# headsail register map
Vendor: tuni.fi; File version: 1.0
CPU: other r1p0, little endian, no MPU, no FPU, vendor SysTick, 2 interrupt priority bits
Registers are 32-bit, read-write, no defined reset value unless marked. A register's access mark holds for its fields unless they carry their own. Offsets are from the block's base; [hi:lo] are bit positions; lines under a group give offsets from that group; {n}, {i} and the like mark numbered series; <NAME> marks a mode.

## DMA0 — The Excel of Register Map can be found here. <https://tuni.sharepoint.com/:x:/r/sites/TG-SoC-Hub/_layouts/15/Doc.aspx?sourcedoc=%7B971A5DEF-758E-4A18-8EA3-0F3F2D60F0BB%7D&file=DMA_register_map.xlsx&action=default&mobileredirect=true&cid=419a13fc-9dbd-45b9-8f31-77899c555ace> DMA Sub System Document available in below link: <https://tuni.sharepoint.com/:w:/r/sites/TG-SoC-Hub/_layouts/15/Doc.aspx?sourcedoc=%7B9E9DFD0D-B0CA-436B-ABA0-57DB3B73560E%7D&file=DMA_Sub_System_Document.....docx&action=default&mobileredirect=true>
Base 0x1FFA00000
Same registers: DMA1 0x1FFA08000
0x00 status group
  0x00 IP_ID ro — Constant 32'h70646d61 default value ; "pdma" in ascii
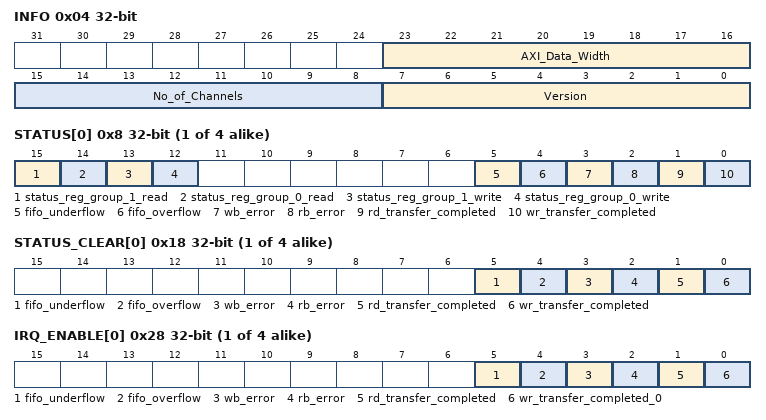
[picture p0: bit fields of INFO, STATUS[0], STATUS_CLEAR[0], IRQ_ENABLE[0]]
  0x04 INFO ro — 32'h00200401 default value Version number Number of available channels AXI data width
    [23:16] AXI_Data_Width, [15:8] No_of_Channels, [7:0] Version
  {0x8+4j} STATUS[{j}] (j=0..3) ro — Holds status flags for Channel(0-3). Each Status Flag can either be cleared by writing to the STATUS_CLEAR register or when the STATUS register is read (must be configured) Status bits of Reg Groups should be read by CPU '0' = Reg Group is Idle '1' = Hardware is using specific reg group
    [15] status_reg_group_1_read, [14] status_reg_group_0_read, [13] status_reg_group_1_write, [12] status_reg_group_0_write, [5] fifo_underflow, [4] fifo_overflow, [3] wb_error, [2] rb_error, [1] rd_transfer_completed, [0] wr_transfer_completed
  {0x18+4j} STATUS_CLEAR[{j}] (j=0..3) — Acknowledging status register for Channels(0-3). Clearing each one by setting corresponding bit
    [5] fifo_underflow, [4] fifo_overflow, [3] wb_error, [2] rb_error, [1] rd_transfer_completed, [0] wr_transfer_completed
  {0x28+4j} IRQ_ENABLE[{j}] (j=0..3) — Configuring which of the interrupts are routed to the IRQ pin for Channels(0-3). Enabling each intterupt signal by setting corresponding bit. All of the interrupts can be enabled and disabled independent from each other.
    [5] fifo_underflow, [4] fifo_overflow, [3] wb_error, [2] rb_error, [1] rd_transfer_completed, [0] wr_transfer_completed_0
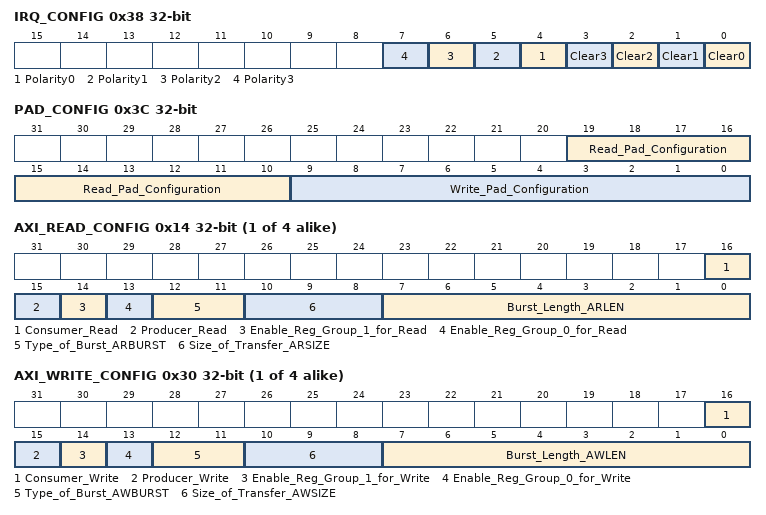
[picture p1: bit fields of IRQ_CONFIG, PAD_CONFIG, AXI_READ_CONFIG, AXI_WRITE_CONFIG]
  0x38 IRQ_CONFIG — Configures the state (active high/low) and clearing conditions for the IRQ pin. Cleared: '0' = Use STATUS_CLEAR to clear '1' = Auto Clear on Read of STATUS register Polarity: '0' = IRQ active low '1' = IRQ active high Set all bits IRQ_CONFIG(7 downto 4) of polarity to "1111" for IRQ active high or "0000" for IRQ active low.
    [n+4] Polarity{n} (n=0..3), [n] Clear{n} (n=0..3)
  0x3C PAD_CONFIG — Configures Pad, 10 Bits for read pad configuration 10 bits for write pad configuration.
    [19:10] Read_Pad_Configuration, [9:0] Write_Pad_Configuration
{0x40+0x80*i} channel{i} group (i=0..3)
  0x00 SOURCE_ADDR — Start address for read
    [31:0] Source_Address
  0x04 SOURCE_LENGTH — Length of read transfer in bytes
  0x08 SOURCE_MODE — ATM only used for initiating a transfer with write to least significant bit. LSB is unset once transfer is started, until then the address and length registers must not be modified.
  0x0C SOURCE_MODE_SET wo — Write to set source mode register
  0x10 SOURCE_MODE_UNSET wo — Write to unset source mode register
  0x14 AXI_READ_CONFIG — AXI configuration signals for read Enable should be done by CPU '0' = Not Enabled specific reg group '1' = Enabling specific reg group. Producer should be updated by CPU '0' = Configuring Reg Group 0 '1' = Configuring Reg Group 1 Consumer should be read by CPU '0' = Hardware source output by Reg Group 0 '1' = Hardware source output by Reg Group 1
    [16] Consumer_Read, [15] Producer_Read, [14] Enable_Reg_Group_1_for_Read, [13] Enable_Reg_Group_0_for_Read, [12:11] Type_of_Burst_ARBURST, [10:8] Size_of_Transfer_ARSIZE, [7:0] Burst_Length_ARLEN
  0x1C DESTINATION_ADDR — Start address for write
    [31:0] Destination_Address
  0x20 DESTINATION_LENGTH — Length of write transfer in bytes
  0x24 DESTINATION_MODE — ATM only used for initiating a transfer with write to least significant bit. LSB is unset once transfer is started, until then the address and length registers must not be modified.
  0x28 DESTINATION_MODE_SET wo — Write to set destination mode register
  0x2C DESTINATION_MODE_UNSET wo — Write to unset destination mode register
  0x30 AXI_WRITE_CONFIG — AXI configuration signals for write Enable should be done by CPU '0' = Not Enabled specific reg group '1' = Enabling specific reg group. Producer should be updated by CPU '0' = Configuring Reg Group 0 '1' = Configuring Reg Group 1 Consumer should be read by CPU '0' = Hardware source output by Reg Group 0 '1' = Hardware source output by Reg Group 1
    [16] Consumer_Write, [15] Producer_Write, [14] Enable_Reg_Group_1_for_Write, [13] Enable_Reg_Group_0_for_Write, [12:11] Type_of_Burst_AWBURST, [10:8] Size_of_Transfer_AWSIZE, [7:0] Burst_Length_AWLEN
  0x40 D_SOURCE_ADDR — Start address for read
    [31:0] Source_Address_0
  0x44 D_SOURCE_LENGTH — Length of read transfer in bytes
    [31:0] Source_Length
  0x48 D_SOURCE_MODE — ATM only used for initiating a transfer with write to least significant bit. LSB is unset once transfer is started, until then the address and length registers must not be modified.
    [31:0] Source_Mode
  0x4C D_SOURCE_MODE_SET wo — Write to set source mode register
    [31:0] Source_Mode_Set
  0x50 D_SOURCE_MODE_UNSET wo — Write to unset source mode register
    [31:0] Source_Mode_Unset
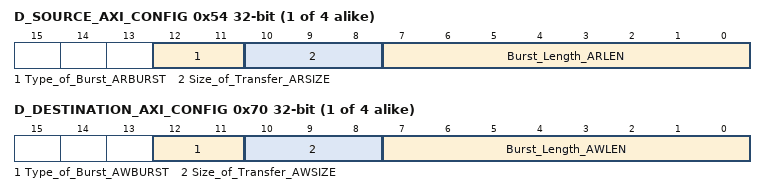
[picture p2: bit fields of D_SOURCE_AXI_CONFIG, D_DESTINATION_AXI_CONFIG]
  0x54 D_SOURCE_AXI_CONFIG — AXI configuration signals for read Enable should be done by CPU '0' = Not Enabled specific reg group '1' = Enabling specific reg group. Producer should be updated by CPU '0' = Configuring Reg Group 0 '1' = Configuring Reg Group 1 Consumer should be read by CPU '0' = Hardware source output by Reg Group 0 '1' = Hardware source output by Reg Group 1
    [12:11] Type_of_Burst_ARBURST, [10:8] Size_of_Transfer_ARSIZE, [7:0] Burst_Length_ARLEN
  0x5C D_DESTINATION_ADDR — Start address for write
    [31:0] Destination_Address
  0x60 D_DESTINATION_LENGTH — Length of write transfer in bytes
    [31:0] Destination_Length
  0x64 D_DESTINATION_MODE — ATM only used for initiating a transfer with write to least significant bit. LSB is unset once transfer is started, until then the address and length registers must not be modified.
    [31:0] Destination_Mode
  0x68 D_DESTINATION_MODE_SET wo — Write to set destination mode register
    [31:0] Destination_Mode_Set
  0x6C D_DESTINATION_MODE_UNSET wo — Write to unset destination mode register
    [31:0] Destination_Mode_Unset
  0x70 D_DESTINATION_AXI_CONFIG — AXI configuration signals for write Enable should be done by CPU '0' = Not Enabled specific reg group '1' = Enabling specific reg group. Producer should be updated by CPU '0' = Configuring Reg Group 0 '1' = Configuring Reg Group 1 Consumer should be read by CPU '0' = Hardware source output by Reg Group 0 '1' = Hardware source output by Reg Group 1
    [12:11] Type_of_Burst_AWBURST, [10:8] Size_of_Transfer_AWSIZE, [7:0] Burst_Length_AWLEN
